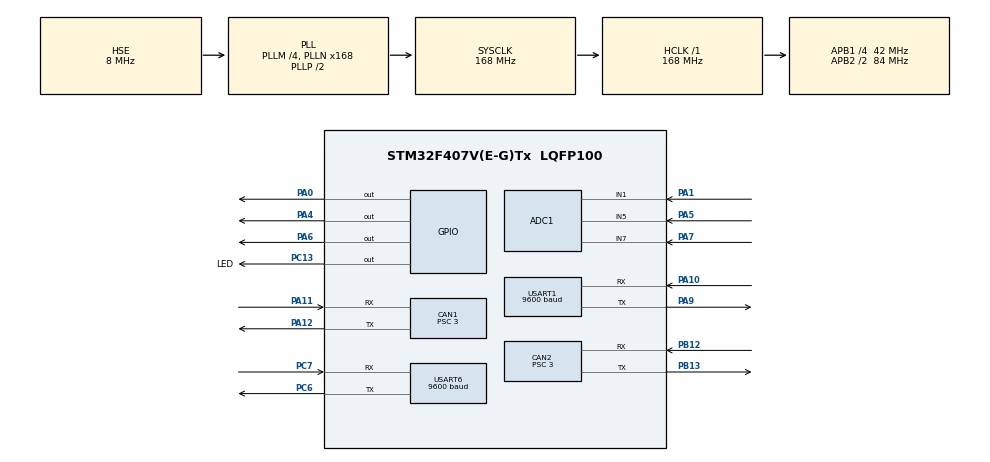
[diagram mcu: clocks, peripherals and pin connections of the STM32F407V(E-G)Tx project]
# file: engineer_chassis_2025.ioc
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ADC1.Channel-0\#ChannelRegularConversion=ADC_CHANNEL_7
ADC1.Channel-1\#ChannelRegularConversion=ADC_CHANNEL_5
ADC1.Channel-2\#ChannelRegularConversion=ADC_CHANNEL_1
ADC1.ClockPrescaler=ADC_CLOCK_SYNC_PCLK_DIV6
ADC1.ContinuousConvMode=ENABLE
ADC1.DMAContinuousRequests=ENABLE
ADC1.DataAlign=ADC_DATAALIGN_RIGHT
ADC1.DiscontinuousConvMode=DISABLE
ADC1.EOCSelection=ADC_EOC_SEQ_CONV
ADC1.NbrOfConversion=3
ADC1.NbrOfConversionFlag=1
ADC1.Rank-0\#ChannelRegularConversion=1
ADC1.Rank-1\#ChannelRegularConversion=2
ADC1.Rank-2\#ChannelRegularConversion=3
ADC1.SamplingTime-0\#ChannelRegularConversion=ADC_SAMPLETIME_15CYCLES
ADC1.SamplingTime-1\#ChannelRegularConversion=ADC_SAMPLETIME_15CYCLES
ADC1.SamplingTime-2\#ChannelRegularConversion=ADC_SAMPLETIME_15CYCLES
ADC1.ScanConvMode=ENABLE
ADC1.master=1
CAN1.ABOM=ENABLE
CAN1.AWUM=ENABLE
CAN1.BS1=CAN_BS1_7TQ
CAN1.BS2=CAN_BS2_6TQ
CAN1.CalculateBaudRate=1000000
CAN1.CalculateTimeBit=1000
CAN1.CalculateTimeQuantum=71.42857142857143
CAN1.NART=ENABLE
CAN1.Prescaler=3
CAN1.TXFP=ENABLE
CAN2.ABOM=ENABLE
CAN2.AWUM=ENABLE
CAN2.BS1=CAN_BS1_7TQ
CAN2.BS2=CAN_BS2_6TQ
CAN2.CalculateBaudRate=1000000
CAN2.CalculateTimeBit=1000
CAN2.CalculateTimeQuantum=71.42857142857143
CAN2.NART=ENABLE
CAN2.Prescaler=3
CAN2.TXFP=ENABLE
Dma.ADC1.0.Direction=DMA_PERIPH_TO_MEMORY
Dma.ADC1.0.FIFOMode=DMA_FIFOMODE_DISABLE
Dma.ADC1.0.Instance=DMA2_Stream0
Dma.ADC1.0.MemDataAlignment=DMA_MDATAALIGN_HALFWORD
Dma.ADC1.0.MemInc=DMA_MINC_ENABLE
Dma.ADC1.0.Mode=DMA_CIRCULAR
Dma.ADC1.0.PeriphDataAlignment=DMA_PDATAALIGN_HALFWORD
Dma.ADC1.0.PeriphInc=DMA_PINC_DISABLE
Dma.ADC1.0.Priority=DMA_PRIORITY_HIGH
Dma.Request0=ADC1
Dma.Request1=USART1_RX
Dma.Request2=USART1_TX
Dma.Request3=USART6_RX
Dma.Request4=USART6_TX
Dma.USART1_RX.1.Direction=DMA_PERIPH_TO_MEMORY
Dma.USART1_RX.1.FIFOMode=DMA_FIFOMODE_DISABLE
Dma.USART1_RX.1.Instance=DMA2_Stream2
Dma.USART1_RX.1.MemDataAlignment=DMA_MDATAALIGN_BYTE
Dma.USART1_RX.1.MemInc=DMA_MINC_ENABLE
Dma.USART1_RX.1.Mode=DMA_NORMAL
Dma.USART1_RX.1.PeriphDataAlignment=DMA_PDATAALIGN_BYTE
Dma.USART1_RX.1.PeriphInc=DMA_PINC_DISABLE
Dma.USART1_RX.1.Priority=DMA_PRIORITY_HIGH
Dma.USART1_TX.2.Direction=DMA_MEMORY_TO_PERIPH
Dma.USART1_TX.2.FIFOMode=DMA_FIFOMODE_DISABLE
Dma.USART1_TX.2.Instance=DMA2_Stream7
Dma.USART1_TX.2.MemDataAlignment=DMA_MDATAALIGN_BYTE
Dma.USART1_TX.2.MemInc=DMA_MINC_ENABLE
Dma.USART1_TX.2.Mode=DMA_NORMAL
Dma.USART1_TX.2.PeriphDataAlignment=DMA_PDATAALIGN_BYTE
Dma.USART1_TX.2.PeriphInc=DMA_PINC_DISABLE
Dma.USART1_TX.2.Priority=DMA_PRIORITY_HIGH
Dma.USART6_RX.3.Direction=DMA_PERIPH_TO_MEMORY
Dma.USART6_RX.3.FIFOMode=DMA_FIFOMODE_DISABLE
Dma.USART6_RX.3.Instance=DMA2_Stream1
Dma.USART6_RX.3.MemDataAlignment=DMA_MDATAALIGN_BYTE
Dma.USART6_RX.3.MemInc=DMA_MINC_ENABLE
Dma.USART6_RX.3.Mode=DMA_NORMAL
Dma.USART6_RX.3.PeriphDataAlignment=DMA_PDATAALIGN_BYTE
Dma.USART6_RX.3.PeriphInc=DMA_PINC_DISABLE
Dma.USART6_RX.3.Priority=DMA_PRIORITY_HIGH
Dma.USART6_TX.4.Direction=DMA_MEMORY_TO_PERIPH
Dma.USART6_TX.4.FIFOMode=DMA_FIFOMODE_DISABLE
Dma.USART6_TX.4.Instance=DMA2_Stream6
Dma.USART6_TX.4.MemDataAlignment=DMA_MDATAALIGN_BYTE
Dma.USART6_TX.4.MemInc=DMA_MINC_ENABLE
Dma.USART6_TX.4.Mode=DMA_NORMAL
Dma.USART6_TX.4.PeriphDataAlignment=DMA_PDATAALIGN_BYTE
Dma.USART6_TX.4.PeriphInc=DMA_PINC_DISABLE
Dma.USART6_TX.4.Priority=DMA_PRIORITY_HIGH
FREERTOS.BinarySemaphores01=adcUpdateBinarySem,Dynamic,NULL,Depleted;ChassisMotor1UpdateBinarySem,Dynamic,NULL,Depleted;ChassisMotor2UpdateBinarySem,Dynamic,NULL,Depleted;ChassisMotor3UpdateBinarySem,Dynamic,NULL,Depleted;ChassisMotor4UpdateBinarySem,Dynamic,NULL,Depleted;IMUUpdateBinarySem,Dynamic,NULL,Depleted;CommunicateUpdateBinarySem,Dynamic,NULL,Depleted
FREERTOS.CountingSemaphores01=CAN1CountingSem,3,Dynamic,NULL,3;CAN2CountingSem,3,Dynamic,NULL,3
FREERTOS.Queues01=CAN1SendQueue,16,can_device_transmit_member,0,Dynamic,NULL,NULL;CAN2SendQueue,16,can_device_transmit_member,0,Dynamic,NULL,NULL
FREERTOS.Tasks01=defaultTask,24,128,StartDefaultTask,Default,NULL,Dynamic,NULL,NULL;pumptask,24,128,pump_task,As weak,NULL,Dynamic,NULL,NULL;CAN1SendTask,40,128,CAN1Send_Task,As weak,NULL,Dynamic,NULL,NULL;CAN2SendTask,40,128,CAN2Send_Task,As weak,NULL,Dynamic,NULL,NULL;chassistask,24,256,chassis_task,As weak,NULL,Dynamic,NULL,NULL;lostcheck_task,24,512,lost_check_task,As weak,NULL,Dynamic,NULL,NULL;communicatetask,24,512,communicate_task,As weak,NULL,Dynamic,NULL,NULL
FREERTOS.configTOTAL_HEAP_SIZE=64000
FREERTOS.configUSE_NEWLIB_REENTRANT=1
Mcu.Family=STM32F4
Mcu.Name=STM32F407V(E-G)Tx
Mcu.Package=LQFP100
NVIC.CAN1_RX0_IRQn=true\:5\:0\:false\:false\:true\:true\:true\:true\:true
NVIC.CAN1_TX_IRQn=true\:5\:0\:false\:false\:true\:true\:true\:true\:true
NVIC.CAN2_RX1_IRQn=true\:5\:0\:false\:false\:true\:true\:true\:true\:true
NVIC.CAN2_TX_IRQn=true\:5\:0\:false\:false\:true\:true\:true\:true\:true
NVIC.DMA2_Stream0_IRQn=true\:5\:0\:false\:false\:true\:true\:false\:true\:true
NVIC.DMA2_Stream1_IRQn=true\:5\:0\:false\:false\:true\:true\:false\:true\:true
NVIC.DMA2_Stream2_IRQn=true\:5\:0\:false\:false\:true\:true\:false\:true\:true
NVIC.DMA2_Stream6_IRQn=true\:5\:0\:false\:false\:true\:true\:false\:true\:true
NVIC.DMA2_Stream7_IRQn=true\:5\:0\:false\:false\:true\:true\:false\:true\:true
NVIC.PriorityGroup=NVIC_PRIORITYGROUP_4
NVIC.TIM7_IRQn=true\:15\:0\:false\:false\:true\:false\:false\:true\:true
NVIC.TimeBase=TIM7_IRQn
NVIC.TimeBaseIP=TIM7
NVIC.USART1_IRQn=true\:5\:0\:false\:false\:true\:true\:true\:true\:true
NVIC.USART6_IRQn=true\:5\:0\:false\:false\:true\:true\:true\:true\:true
PA0-WKUP.Signal=GPIO_Output
PA1.Signal=ADCx_IN1
PA10.Mode=Asynchronous
PA10.Signal=USART1_RX
PA11.Mode=CAN_Activate
PA11.Signal=CAN1_RX
PA12.Mode=CAN_Activate
PA12.Signal=CAN1_TX
PA13.Mode=Serial_Wire
PA13.Signal=SYS_JTMS-SWDIO
PA14.Mode=Serial_Wire
PA14.Signal=SYS_JTCK-SWCLK
PA4.Signal=GPIO_Output
PA5.Signal=ADCx_IN5
PA6.Signal=GPIO_Output
PA7.Signal=ADCx_IN7
PA9.Mode=Asynchronous
PA9.Signal=USART1_TX
PB12.Mode=CAN_Activate
PB12.Signal=CAN2_RX
PB13.Mode=CAN_Activate
PB13.Signal=CAN2_TX
PC13-ANTI_TAMP.GPIO_Label=LED
PC13-ANTI_TAMP.Signal=GPIO_Output
PC6.Mode=Asynchronous
PC6.Signal=USART6_TX
PC7.Mode=Asynchronous
PC7.Signal=USART6_RX
PH0-OSC_IN.Mode=HSE-External-Oscillator
PH0-OSC_IN.Signal=RCC_OSC_IN
PH1-OSC_OUT.Mode=HSE-External-Oscillator
PH1-OSC_OUT.Signal=RCC_OSC_OUT
ProjectManager.HeapSize=0x200
ProjectManager.StackSize=0x400
ProjectManager.TargetToolchain=STM32CubeIDE
RCC.48MHZClocksFreq_Value=84000000
RCC.AHBFreq_Value=168000000
RCC.APB1CLKDivider=RCC_HCLK_DIV4
RCC.APB1Freq_Value=42000000
RCC.APB1TimFreq_Value=84000000
RCC.APB2CLKDivider=RCC_HCLK_DIV2
RCC.APB2Freq_Value=84000000
RCC.APB2TimFreq_Value=168000000
RCC.CortexFreq_Value=168000000
RCC.HCLKFreq_Value=168000000
RCC.HSE_VALUE=8000000
RCC.HSI_VALUE=16000000
RCC.LSE_VALUE=32768
RCC.PLLM=4
RCC.PLLN=168
RCC.PLLSourceVirtual=RCC_PLLSOURCE_HSE
RCC.SYSCLKFreq_VALUE=168000000
RCC.SYSCLKSource=RCC_SYSCLKSOURCE_PLLCLK
RCC.VCOOutputFreq_Value=336000000
SH.ADCx_IN1.0=ADC1_IN1,IN1
SH.ADCx_IN5.0=ADC1_IN5,IN5
SH.ADCx_IN7.0=ADC1_IN7,IN7
STMicroelectronics.X-CUBE-ALGOBUILD.1.4.0.LibraryCcDSPOoLibraryJjDSPOoLibrary=true
USART1.BaudRate=9600
USART1.VirtualMode=VM_ASYNC
USART6.BaudRate=9600
USART6.VirtualMode=VM_ASYNC
VP_FREERTOS_VS_CMSIS_V2.Mode=CMSIS_V2
VP_IWDG_VS_IWDG.Mode=IWDG_Activate
VP_STMicroelectronics.X-CUBE-ALGOBUILD_VS_DSPOoLibraryJjLibrary_1.4.0_1.4.0.Mode=DSPOoLibraryJjLibrary
VP_SYS_VS_tim7.Mode=TIM7
board=custom

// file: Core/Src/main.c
/* USER CODE BEGIN Header */
/**
  ******************************************************************************
  * @file           : main.c
  * @brief          : Main program body
  ******************************************************************************
  * @attention
  *
  * Copyright (c) 2025 STMicroelectronics.
  * All rights reserved.
  *
  * This software is licensed under terms that can be found in the LICENSE file
  * in the root directory of this software component.
  * If no LICENSE file comes with this software, it is provided AS-IS.
  *
  ******************************************************************************
  */
/* USER CODE END Header */
#include "main.h"
#include "cmsis_os.h"
#include "adc.h"
#include "can.h"
#include "dma.h"
#include "iwdg.h"
#include "usart.h"
#include "gpio.h"

/* USER CODE BEGIN Includes */
#include "compatible.h"
#include "bsp_dwt.h"
/* USER CODE END Includes */

void SystemClock_Config(void);
void MX_FREERTOS_Init(void);

int main(void)
{

  /* USER CODE BEGIN 1 */
    __HAL_RCC_SYSCLK_CONFIG(RCC_SYSCLKSOURCE_HSI);
  /* USER CODE END 1 */

  /* MCU Configuration--------------------------------------------------------*/

  /* Reset of all peripherals, Initializes the Flash interface and the Systick. */
  HAL_Init();

  /* Configure the system clock */
  SystemClock_Config();

  /* Initialize all configured peripherals */
  MX_GPIO_Init();
  MX_DMA_Init();
  MX_ADC1_Init();
  MX_CAN1_Init();
  MX_CAN2_Init();
  MX_USART1_UART_Init();
  MX_USART6_UART_Init();
  // MX_IWDG_Init();
  /* USER CODE BEGIN 2 */
    DWT_Init(168);
    bsp_can_init();
  /* USER CODE END 2 */

  /* Init scheduler */
  osKernelInitialize();  /* Call init function for freertos objects (in cmsis_os2.c) */
  MX_FREERTOS_Init();

  /* Start scheduler */
  osKernelStart();

  /* We should never get here as control is now taken by the scheduler */

  /* Infinite loop */
  while (1)
  {

  }
}

void SystemClock_Config(void)
{
  RCC_OscInitTypeDef RCC_OscInitStruct = {0};
  RCC_ClkInitTypeDef RCC_ClkInitStruct = {0};

  /** Configure the main internal regulator output voltage
  */
  __HAL_RCC_PWR_CLK_ENABLE();
  __HAL_PWR_VOLTAGESCALING_CONFIG(PWR_REGULATOR_VOLTAGE_SCALE1);

  /** Initializes the RCC Oscillators according to the specified parameters
  * in the RCC_OscInitTypeDef structure.
  */
  RCC_OscInitStruct.OscillatorType = RCC_OSCILLATORTYPE_LSI|RCC_OSCILLATORTYPE_HSE;
  RCC_OscInitStruct.HSEState = RCC_HSE_ON;
  RCC_OscInitStruct.LSIState = RCC_LSI_ON;
  RCC_OscInitStruct.PLL.PLLState = RCC_PLL_ON;
  RCC_OscInitStruct.PLL.PLLSource = RCC_PLLSOURCE_HSE;
  RCC_OscInitStruct.PLL.PLLM = 4;
  RCC_OscInitStruct.PLL.PLLN = 168;
  RCC_OscInitStruct.PLL.PLLP = RCC_PLLP_DIV2;
  RCC_OscInitStruct.PLL.PLLQ = 4;
  if (HAL_RCC_OscConfig(&RCC_OscInitStruct) != HAL_OK)
  {
    Error_Handler();
  }

  /** Initializes the CPU, AHB and APB buses clocks
  */
  RCC_ClkInitStruct.ClockType = RCC_CLOCKTYPE_HCLK|RCC_CLOCKTYPE_SYSCLK
                              |RCC_CLOCKTYPE_PCLK1|RCC_CLOCKTYPE_PCLK2;
  RCC_ClkInitStruct.SYSCLKSource = RCC_SYSCLKSOURCE_PLLCLK;
  RCC_ClkInitStruct.AHBCLKDivider = RCC_SYSCLK_DIV1;
  RCC_ClkInitStruct.APB1CLKDivider = RCC_HCLK_DIV4;
  RCC_ClkInitStruct.APB2CLKDivider = RCC_HCLK_DIV2;

  if (HAL_RCC_ClockConfig(&RCC_ClkInitStruct, FLASH_LATENCY_5) != HAL_OK)
  {
    Error_Handler();
  }
}

void HAL_TIM_PeriodElapsedCallback(TIM_HandleTypeDef *htim)
{
  if (htim->Instance == TIM7)
  {
    HAL_IncTick();
  }
}

void Error_Handler(void)
{
  __disable_irq();
  while (1)
  {
  }
}

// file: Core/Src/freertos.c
/* USER CODE BEGIN Header */
/**
  ******************************************************************************
  * File Name          : freertos.c
  * Description        : Code for freertos applications
  ******************************************************************************
  * @attention
  *
  * Copyright (c) 2025 STMicroelectronics.
  * All rights reserved.
  *
  * This software is licensed under terms that can be found in the LICENSE file
  * in the root directory of this software component.
  * If no LICENSE file comes with this software, it is provided AS-IS.
  *
  ******************************************************************************
  */
/* USER CODE END Header */

#include "FreeRTOS.h"
#include "task.h"
#include "main.h"
#include "cmsis_os.h"

/* USER CODE BEGIN Includes */
#include "compatible.h"
/* USER CODE END Includes */

/* Definitions for defaultTask */
osThreadId_t defaultTaskHandle;
const osThreadAttr_t defaultTask_attributes = {
  .name = "defaultTask",
  .stack_size = 128 * 4,
  .priority = (osPriority_t) osPriorityNormal,
};
/* Definitions for pumptask */
osThreadId_t pumptaskHandle;
const osThreadAttr_t pumptask_attributes = {
  .name = "pumptask",
  .stack_size = 128 * 4,
  .priority = (osPriority_t) osPriorityNormal,
};
/* Definitions for CAN1SendTask */
osThreadId_t CAN1SendTaskHandle;
const osThreadAttr_t CAN1SendTask_attributes = {
  .name = "CAN1SendTask",
  .stack_size = 128 * 4,
  .priority = (osPriority_t) osPriorityHigh,
};
/* Definitions for CAN2SendTask */
osThreadId_t CAN2SendTaskHandle;
const osThreadAttr_t CAN2SendTask_attributes = {
  .name = "CAN2SendTask",
  .stack_size = 128 * 4,
  .priority = (osPriority_t) osPriorityHigh,
};
/* Definitions for chassistask */
osThreadId_t chassistaskHandle;
const osThreadAttr_t chassistask_attributes = {
  .name = "chassistask",
  .stack_size = 256 * 4,
  .priority = (osPriority_t) osPriorityNormal,
};
/* Definitions for lostcheck_task */
osThreadId_t lostcheck_taskHandle;
const osThreadAttr_t lostcheck_task_attributes = {
  .name = "lostcheck_task",
  .stack_size = 512 * 4,
  .priority = (osPriority_t) osPriorityNormal,
};
/* Definitions for communicatetask */
osThreadId_t communicatetaskHandle;
const osThreadAttr_t communicatetask_attributes = {
  .name = "communicatetask",
  .stack_size = 512 * 4,
  .priority = (osPriority_t) osPriorityNormal,
};
/* Definitions for CAN1SendQueue */
osMessageQueueId_t CAN1SendQueueHandle;
const osMessageQueueAttr_t CAN1SendQueue_attributes = {
  .name = "CAN1SendQueue"
};
/* Definitions for CAN2SendQueue */
osMessageQueueId_t CAN2SendQueueHandle;
const osMessageQueueAttr_t CAN2SendQueue_attributes = {
  .name = "CAN2SendQueue"
};
/* Definitions for adcUpdateBinarySem */
osSemaphoreId_t adcUpdateBinarySemHandle;
const osSemaphoreAttr_t adcUpdateBinarySem_attributes = {
  .name = "adcUpdateBinarySem"
};
/* Definitions for ChassisMotor1UpdateBinarySem */
osSemaphoreId_t ChassisMotor1UpdateBinarySemHandle;
const osSemaphoreAttr_t ChassisMotor1UpdateBinarySem_attributes = {
  .name = "ChassisMotor1UpdateBinarySem"
};
/* Definitions for ChassisMotor2UpdateBinarySem */
osSemaphoreId_t ChassisMotor2UpdateBinarySemHandle;
const osSemaphoreAttr_t ChassisMotor2UpdateBinarySem_attributes = {
  .name = "ChassisMotor2UpdateBinarySem"
};
/* Definitions for ChassisMotor3UpdateBinarySem */
osSemaphoreId_t ChassisMotor3UpdateBinarySemHandle;
const osSemaphoreAttr_t ChassisMotor3UpdateBinarySem_attributes = {
  .name = "ChassisMotor3UpdateBinarySem"
};
/* Definitions for ChassisMotor4UpdateBinarySem */
osSemaphoreId_t ChassisMotor4UpdateBinarySemHandle;
const osSemaphoreAttr_t ChassisMotor4UpdateBinarySem_attributes = {
  .name = "ChassisMotor4UpdateBinarySem"
};
/* Definitions for IMUUpdateBinarySem */
osSemaphoreId_t IMUUpdateBinarySemHandle;
const osSemaphoreAttr_t IMUUpdateBinarySem_attributes = {
  .name = "IMUUpdateBinarySem"
};
/* Definitions for CommunicateUpdateBinarySem */
osSemaphoreId_t CommunicateUpdateBinarySemHandle;
const osSemaphoreAttr_t CommunicateUpdateBinarySem_attributes = {
  .name = "CommunicateUpdateBinarySem"
};
/* Definitions for CAN1CountingSem */
osSemaphoreId_t CAN1CountingSemHandle;
const osSemaphoreAttr_t CAN1CountingSem_attributes = {
  .name = "CAN1CountingSem"
};
/* Definitions for CAN2CountingSem */
osSemaphoreId_t CAN2CountingSemHandle;
const osSemaphoreAttr_t CAN2CountingSem_attributes = {
  .name = "CAN2CountingSem"
};

void StartDefaultTask(void *argument);
void pump_task(void *argument);
void CAN1Send_Task(void *argument);
void CAN2Send_Task(void *argument);
void chassis_task(void *argument);
void lost_check_task(void *argument);
void communicate_task(void *argument);

void MX_FREERTOS_Init(void); /* (MISRA C 2004 rule 8.1) */

void MX_FREERTOS_Init(void) {

  /* Create the semaphores(s) */
  /* creation of adcUpdateBinarySem */
  adcUpdateBinarySemHandle = osSemaphoreNew(1, 0, &adcUpdateBinarySem_attributes);

  /* creation of ChassisMotor1UpdateBinarySem */
  ChassisMotor1UpdateBinarySemHandle = osSemaphoreNew(1, 0, &ChassisMotor1UpdateBinarySem_attributes);

  /* creation of ChassisMotor2UpdateBinarySem */
  ChassisMotor2UpdateBinarySemHandle = osSemaphoreNew(1, 0, &ChassisMotor2UpdateBinarySem_attributes);

  /* creation of ChassisMotor3UpdateBinarySem */
  ChassisMotor3UpdateBinarySemHandle = osSemaphoreNew(1, 0, &ChassisMotor3UpdateBinarySem_attributes);

  /* creation of ChassisMotor4UpdateBinarySem */
  ChassisMotor4UpdateBinarySemHandle = osSemaphoreNew(1, 0, &ChassisMotor4UpdateBinarySem_attributes);

  /* creation of IMUUpdateBinarySem */
  IMUUpdateBinarySemHandle = osSemaphoreNew(1, 0, &IMUUpdateBinarySem_attributes);

  /* creation of CommunicateUpdateBinarySem */
  CommunicateUpdateBinarySemHandle = osSemaphoreNew(1, 0, &CommunicateUpdateBinarySem_attributes);

  /* creation of CAN1CountingSem */
  CAN1CountingSemHandle = osSemaphoreNew(3, 3, &CAN1CountingSem_attributes);

  /* creation of CAN2CountingSem */
  CAN2CountingSemHandle = osSemaphoreNew(3, 3, &CAN2CountingSem_attributes);

  /* Create the queue(s) */
  /* creation of CAN1SendQueue */
  CAN1SendQueueHandle = osMessageQueueNew (16, sizeof(can_device_transmit_member), &CAN1SendQueue_attributes);

  /* creation of CAN2SendQueue */
  CAN2SendQueueHandle = osMessageQueueNew (16, sizeof(can_device_transmit_member), &CAN2SendQueue_attributes);

  /* Create the thread(s) */
  /* creation of defaultTask */
  defaultTaskHandle = osThreadNew(StartDefaultTask, NULL, &defaultTask_attributes);

  /* creation of pumptask */
  pumptaskHandle = osThreadNew(pump_task, NULL, &pumptask_attributes);

  /* creation of CAN1SendTask */
  CAN1SendTaskHandle = osThreadNew(CAN1Send_Task, NULL, &CAN1SendTask_attributes);

  /* creation of CAN2SendTask */
  CAN2SendTaskHandle = osThreadNew(CAN2Send_Task, NULL, &CAN2SendTask_attributes);

  /* creation of chassistask */
  chassistaskHandle = osThreadNew(chassis_task, NULL, &chassistask_attributes);

  /* creation of lostcheck_task */
  lostcheck_taskHandle = osThreadNew(lost_check_task, NULL, &lostcheck_task_attributes);

  /* creation of communicatetask */
  communicatetaskHandle = osThreadNew(communicate_task, NULL, &communicatetask_attributes);

}

void StartDefaultTask(void *argument)
{
  /* USER CODE BEGIN StartDefaultTask */
  /* Infinite loop */
  for(;;)
  {
      HAL_GPIO_TogglePin(LED_GPIO_Port,LED_Pin);
    osDelay(500);
  }
  /* USER CODE END StartDefaultTask */
}

__weak void pump_task(void *argument)
{
  for(;;)
  {
    osDelay(1);
  }
}

__weak void CAN1Send_Task(void *argument)
{
  for(;;)
  {
    osDelay(1);
  }
}

__weak void CAN2Send_Task(void *argument)
{
  for(;;)
  {
    osDelay(1);
  }
}

__weak void chassis_task(void *argument)
{
  for(;;)
  {
    osDelay(1);
  }
}

__weak void lost_check_task(void *argument)
{
  for(;;)
  {
    osDelay(1);
  }
}

__weak void communicate_task(void *argument)
{
  for(;;)
  {
    osDelay(1);
  }
}
